# STM32F103 register map
File version: 1.1
CPU: CM3 r1p1, little endian, no MPU, no FPU, 4 interrupt priority bits
Registers are 32-bit, read-write, reset 0x0 unless marked. A register's access mark holds for its fields unless they carry their own. Offsets are from the block's base; [hi:lo] are bit positions; {n}, {i} and the like mark numbered series; 'fields as' and 'values as' point back to an identical list.

## RCC — Reset and clock control
Base 0x40021000
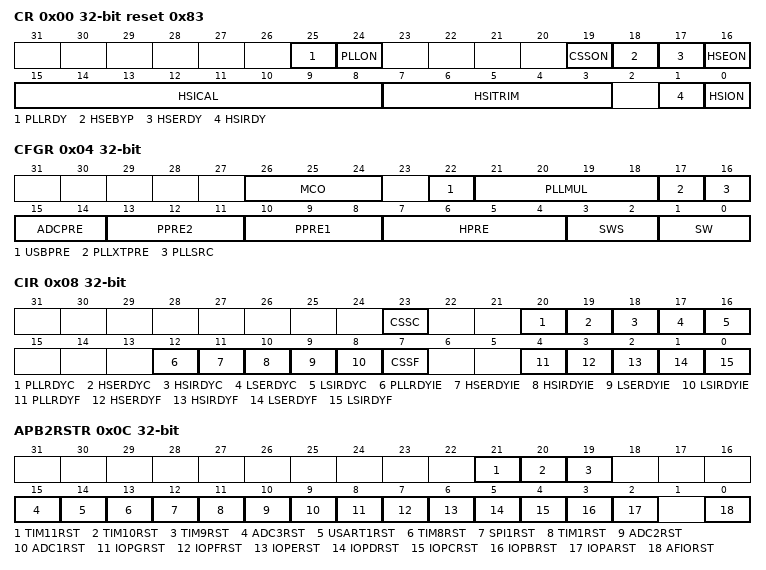
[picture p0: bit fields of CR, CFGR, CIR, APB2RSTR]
0x00 CR access per field reset 0x83 — Clock control register
  [25] PLLRDY ro — PLL clock ready flag
    0=NotReady (Clock not ready); 1=Ready (Clock ready)
  [24] PLLON rw — PLL enable
    0=Off (Clock Off); 1=On (Clock On)
  [19] CSSON rw — Clock Security System enable
    0=Off (Clock security system disabled (clock detector OFF)); 1=On (Clock security system enable (clock detector ON if the HSE is ready, OFF if not))
  [18] HSEBYP rw — External High Speed clock Bypass
    0=NotBypassed (HSE crystal oscillator not bypassed); 1=Bypassed (HSE crystal oscillator bypassed with external clock)
  [17] HSERDY ro — External High Speed clock ready flag
    0=NotReady (Clock not ready); 1=Ready (Clock ready)
  [16] HSEON rw — External High Speed clock enable
    0=Off (Clock Off); 1=On (Clock On)
  [15:8] HSICAL ro — Internal High Speed clock Calibration
  [7:3] HSITRIM rw — Internal High Speed clock trimming
  [1] HSIRDY ro — Internal High Speed clock ready flag
    0=NotReady (Clock not ready); 1=Ready (Clock ready)
  [0] HSION rw — Internal High Speed clock enable
    0=Off (Clock Off); 1=On (Clock On)
0x04 CFGR access per field — Clock configuration register (RCC_CFGR)
  [26:24] MCO rw — Microcontroller clock output
    0=NoMCO (MCO output disabled, no clock on MCO); 4=SYSCLK (System clock selected); 5=HSI (HSI oscillator clock selected); 6=HSE (HSE oscillator clock selected); 7=PLL (PLL clock selected (divided by 1 or 2, depending en PLLNODIV))
  [22] USBPRE rw — USB prescaler
    0=DIV1_5 (PLL clock is divided by 1.5); 1=DIV1 (PLL clock is not divided)
  [21:18] PLLMUL rw — PLL Multiplication Factor
    {v}=Mul{v+2} (PLL input clock x{v+2}) (v=0..14); 15=Mul16x (PLL input clock x16)
  [17] PLLXTPRE rw — HSE divider for PLL entry
    0=Div1 (HSE clock not divided); 1=Div2 (HSE clock divided by 2)
  [16] PLLSRC rw — PLL entry clock source
    0=HSI_Div2 (HSI divided by 2 selected as PLL input clock); 1=HSE_Div_PREDIV (HSE divided by PREDIV selected as PLL input clock)
  [15:14] ADCPRE rw — ADC prescaler
    0=Div2 (PCLK2 divided by 2); 1=Div4 (PCLK2 divided by 4); 2=Div6 (PCLK2 divided by 8); 3=Div8 (PCLK2 divided by 16)
  [13:11] PPRE2 rw — APB High speed prescaler (APB2)
    4=Div2 (HCLK divided by 2); 5=Div4 (HCLK divided by 4); 6=Div8 (HCLK divided by 8); 7=Div16 (HCLK divided by 16); other=Div1 (HCLK not divided)
  [10:8] PPRE1 rw — APB Low speed prescaler (APB1)
    values as PPRE2
  [7:4] HPRE rw — AHB prescaler
    8=Div2 (SYSCLK divided by 2); 9=Div4 (SYSCLK divided by 4); 10=Div8 (SYSCLK divided by 8); 11=Div16 (SYSCLK divided by 16); 12=Div64 (SYSCLK divided by 64); 13=Div128 (SYSCLK divided by 128); 14=Div256 (SYSCLK divided by 256); 15=Div512 (SYSCLK divided by 512); other=Div1 (SYSCLK not divided)
  [3:2] SWS ro — System Clock Switch Status
    0=HSI (HSI oscillator used as system clock); 1=HSE (HSE oscillator used as system clock); 2=PLL (PLL used as system clock)
  [1:0] SW rw — System clock Switch
    0=HSI (HSI selected as system clock); 1=HSE (HSE selected as system clock); 2=PLL (PLL selected as system clock)
0x08 CIR access per field — Clock interrupt register (RCC_CIR)
  [23] CSSC wo — Clock security system interrupt clear
    1=Clear CSSF flag
  [20] PLLRDYC wo — PLL Ready Interrupt Clear
    1=Clear interrupt flag
  [19] HSERDYC wo — HSE Ready Interrupt Clear
    1=Clear interrupt flag
  [18] HSIRDYC wo — HSI Ready Interrupt Clear
    1=Clear interrupt flag
  [17] LSERDYC wo — LSE Ready Interrupt Clear
    1=Clear interrupt flag
  [16] LSIRDYC wo — LSI Ready Interrupt Clear
    1=Clear interrupt flag
  [12] PLLRDYIE rw — PLL Ready Interrupt Enable
    0=Disabled (Interrupt disabled); 1=Enabled (Interrupt enabled)
  [11] HSERDYIE rw — HSE Ready Interrupt Enable
    values as PLLRDYIE
  [10] HSIRDYIE rw — HSI Ready Interrupt Enable
    values as PLLRDYIE
  [9] LSERDYIE rw — LSE Ready Interrupt Enable
    values as PLLRDYIE
  [8] LSIRDYIE rw — LSI Ready Interrupt Enable
    values as PLLRDYIE
  [7] CSSF ro — Clock Security System Interrupt flag
    0=NotInterrupted (No clock security interrupt caused by HSE clock failure); 1=Interrupted (Clock security interrupt caused by HSE clock failure)
  [4] PLLRDYF ro — PLL Ready Interrupt flag
    0=NotInterrupted (No clock ready interrupt); 1=Interrupted (Clock ready interrupt)
  [3] HSERDYF ro — HSE Ready Interrupt flag
    values as PLLRDYF
  [2] HSIRDYF ro — HSI Ready Interrupt flag
    values as PLLRDYF
  [1] LSERDYF ro — LSE Ready Interrupt flag
    values as PLLRDYF
  [0] LSIRDYF ro — LSI Ready Interrupt flag
    values as PLLRDYF
0x0C APB2RSTR — APB2 peripheral reset register (RCC_APB2RSTR)
  [all] fields
    1=Reset the selected module
  [21] TIM11RST — TIM11 timer reset
  [20] TIM10RST — TIM10 timer reset
  [19] TIM9RST — TIM9 timer reset
  [15] ADC3RST — ADC 3 interface reset
  [14] USART1RST — USART1 reset
  [13] TIM8RST — TIM8 timer reset
  [12] SPI1RST — SPI 1 reset
  [11] TIM1RST — TIM1 timer reset
  [10] ADC2RST — ADC 2 interface reset
  [9] ADC1RST — ADC 1 interface reset
  [8] IOPGRST — IO port G reset
  [7] IOPFRST — IO port F reset
  [6] IOPERST — IO port E reset
  [5] IOPDRST — IO port D reset
  [4] IOPCRST — IO port C reset
  [3] IOPBRST — IO port B reset
  [2] IOPARST — IO port A reset
  [0] AFIORST — Alternate function I/O reset
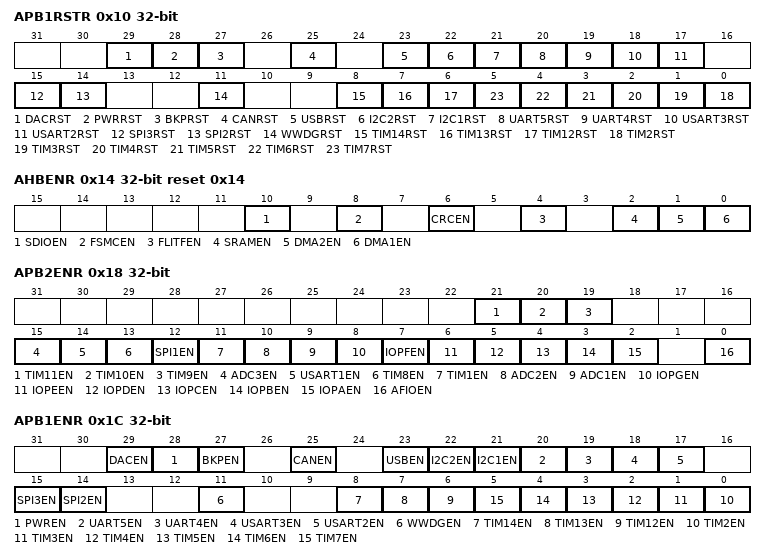
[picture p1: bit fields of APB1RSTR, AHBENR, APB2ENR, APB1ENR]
0x10 APB1RSTR — APB1 peripheral reset register (RCC_APB1RSTR)
  [all] fields
    1=Reset the selected module
  [29] DACRST — DAC interface reset
  [28] PWRRST — Power interface reset
  [27] BKPRST — Backup interface reset
  [25] CANRST — CAN reset
  [23] USBRST — USB reset
  [22] I2C2RST — I2C2 reset
  [21] I2C1RST — I2C1 reset
  [20] UART5RST — UART 5 reset
  [19] UART4RST — UART 4 reset
  [18] USART3RST — USART 3 reset
  [17] USART2RST — USART 2 reset
  [15] SPI3RST — SPI3 reset
  [14] SPI2RST — SPI2 reset
  [11] WWDGRST — Window watchdog reset
  [8] TIM14RST — Timer 14 reset
  [7] TIM13RST — Timer 13 reset
  [6] TIM12RST — Timer 12 reset
  [n-2] TIM{n}RST (n=2..7) — Timer {n} reset
0x14 AHBENR reset 0x14 — AHB Peripheral Clock enable register (RCC_AHBENR)
  [all] fields
    0=Disabled (The selected clock is disabled); 1=Enabled (The selected clock is enabled)
  [10] SDIOEN — SDIO clock enable
  [8] FSMCEN — FSMC clock enable
  [6] CRCEN — CRC clock enable
  [4] FLITFEN — FLITF clock enable
  [2] SRAMEN — SRAM interface clock enable
  [1] DMA2EN — DMA2 clock enable
  [0] DMA1EN — DMA1 clock enable
0x18 APB2ENR — APB2 peripheral clock enable register (RCC_APB2ENR)
  [all] fields
    values as the fields of AHBENR
  [21] TIM11EN — TIM11 Timer clock enable
  [20] TIM10EN — TIM10 Timer clock enable
  [19] TIM9EN — TIM9 Timer clock enable
  [15] ADC3EN — ADC3 interface clock enable
  [14] USART1EN — USART1 clock enable
  [13] TIM8EN — TIM8 Timer clock enable
  [12] SPI1EN — SPI 1 clock enable
  [11] TIM1EN — TIM1 Timer clock enable
  [10] ADC2EN — ADC 2 interface clock enable
  [9] ADC1EN — ADC 1 interface clock enable
  [8] IOPGEN — I/O port G clock enable
  [7] IOPFEN — I/O port F clock enable
  [6] IOPEEN — I/O port E clock enable
  [5] IOPDEN — I/O port D clock enable
  [4] IOPCEN — I/O port C clock enable
  [3] IOPBEN — I/O port B clock enable
  [2] IOPAEN — I/O port A clock enable
  [0] AFIOEN — Alternate function I/O clock enable
0x1C APB1ENR — APB1 peripheral clock enable register (RCC_APB1ENR)
  [all] fields
    values as the fields of AHBENR
  [29] DACEN — DAC interface clock enable
  [28] PWREN — Power interface clock enable
  [27] BKPEN — Backup interface clock enable
  [25] CANEN — CAN clock enable
  [23] USBEN — USB clock enable
  [22] I2C2EN — I2C 2 clock enable
  [21] I2C1EN — I2C 1 clock enable
  [20] UART5EN — UART 5 clock enable
  [19] UART4EN — UART 4 clock enable
  [18] USART3EN — USART 3 clock enable
  [17] USART2EN — USART 2 clock enable
  [15] SPI3EN — SPI 3 clock enable
  [14] SPI2EN — SPI 2 clock enable
  [11] WWDGEN — Window watchdog clock enable
  [8] TIM14EN — Timer 14 clock enable
  [7] TIM13EN — Timer 13 clock enable
  [6] TIM12EN — Timer 12 clock enable
  [n-2] TIM{n}EN (n=2..7) — Timer {n} clock enable
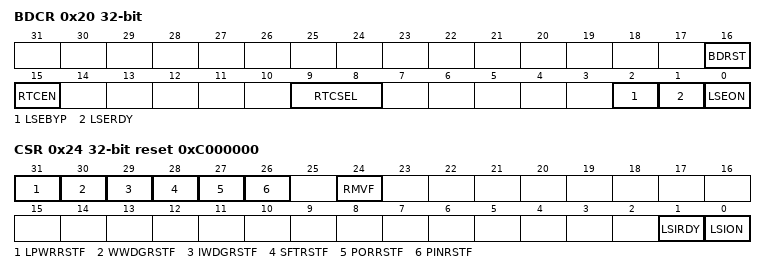
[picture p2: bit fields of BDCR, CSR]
0x20 BDCR access per field — Backup domain control register (RCC_BDCR)
  [16] BDRST rw — Backup domain software reset
    0=Disabled (Reset not activated); 1=Enabled (Reset the entire RTC domain)
  [15] RTCEN rw — RTC clock enable
    0=Disabled (RTC clock disabled); 1=Enabled (RTC clock enabled)
  [9:8] RTCSEL rw — RTC clock source selection
    0=NoClock; 1=LSE (LSE oscillator clock used as RTC clock); 2=LSI (LSI oscillator clock used as RTC clock); 3=HSE (HSE oscillator clock divided by a prescaler used as RTC clock)
  [2] LSEBYP rw — External Low Speed oscillator bypass
    0=NotBypassed (LSE crystal oscillator not bypassed); 1=Bypassed (LSE crystal oscillator bypassed with external clock)
  [1] LSERDY ro — External Low Speed oscillator ready
    0=NotReady (LSE oscillator not ready); 1=Ready (LSE oscillator ready)
  [0] LSEON rw — External Low Speed oscillator enable
    0=Off (LSE oscillator Off); 1=On (LSE oscillator On)
0x24 CSR access per field reset 0xC000000 — Control/status register (RCC_CSR)
  [31] LPWRRSTF rw — Low-power reset flag
    on read: 0=No reset has occured; 1=Reset (A reset has occured)
  [30] WWDGRSTF rw — Window watchdog reset flag
    values as LPWRRSTF
  [29] IWDGRSTF rw — Independent watchdog reset flag
    values as LPWRRSTF
  [28] SFTRSTF rw — Software reset flag
    values as LPWRRSTF
  [27] PORRSTF rw — POR/PDR reset flag
    values as LPWRRSTF
  [26] PINRSTF rw — PIN reset flag
    values as LPWRRSTF
  [24] RMVF rw — Remove reset flag
    on write: 1=Clears the reset flag
  [1] LSIRDY ro — Internal low speed oscillator ready
    0=NotReady (LSI oscillator not ready); 1=Ready (LSI oscillator ready)
  [0] LSION rw — Internal low speed oscillator enable
    0=Off (LSI oscillator Off); 1=On (LSI oscillator On)
